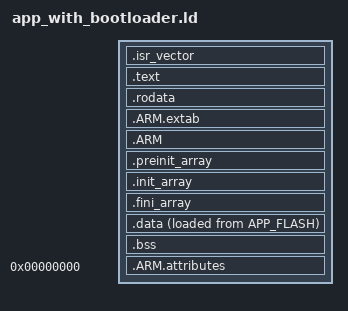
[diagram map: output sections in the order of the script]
/*
*****************************************************************************
**

**  File        : LinkerScript.ld
**
**  Abstract    : Linker script for STM32F4xx Device 
**
**                Set heap size, stack size and stack location according
**                to application requirements.
**
**                Set memory bank area and size if external memory is used.
**
**  Target      : STMicroelectronics STM32
**
**
**  Distribution: The file is distributed as is, without any warranty
**                of any kind.
**
**  (c)Copyright Ac6.
**  You may use this file as-is or modify it according to the needs of your
**  project. Distribution of this file (unmodified or modified) is not
**  permitted. Ac6 permit registered System Workbench for MCU users the
**  rights to distribute the assembled, compiled & linked contents of this
**  file as part of an application binary file, provided that it is built
**  using the System Workbench for MCU toolchain.
**
*****************************************************************************
*/

/* Entry Point */
ENTRY(Reset_Handler)

/* Include memory map */
INCLUDE memory.ld

_Min_Heap_Size = 0x7000;      /* required amount of heap  */
_Min_Stack_Size = 0x1000; /* required amount of stack */

/* Define output sections */
SECTIONS
{

  /* The startup code goes first into FLASH */
  .isr_vector :
  {
    . = ALIGN(8);
    KEEP(*(.isr_vector)) /* Startup code */
    . = ALIGN(8);
  } >APP_FLASH

  /* The program code and other data goes into FLASH */
  .text :
  {
    . = ALIGN(8);
    *(.text)           /* .text sections (code) */
    *(.text*)          /* .text* sections (code) */
    *(.glue_7)         /* glue arm to thumb code */
    *(.glue_7t)        /* glue thumb to arm code */
    *(.eh_frame)

    KEEP (*(.init))
    KEEP (*(.fini))

    . = ALIGN(8);
    _etext = .;        /* define a global symbols at end of code */
  } >APP_FLASH

  /* Constant data goes into FLASH */
  .rodata :
  {
    . = ALIGN(8);
    *(.rodata)         /* .rodata sections (constants, strings, etc.) */
    *(.rodata*)        /* .rodata* sections (constants, strings, etc.) */
    . = ALIGN(8);
  } >APP_FLASH

  .ARM.extab   : 
  { 
  . = ALIGN(8);
  *(.ARM.extab* .gnu.linkonce.armextab.*)
  . = ALIGN(8);
  } >APP_FLASH
  .ARM : {
	. = ALIGN(8);
    __exidx_start = .;
    *(.ARM.exidx*)
    __exidx_end = .;
	. = ALIGN(8);
  } >APP_FLASH

  .preinit_array     :
  {
	. = ALIGN(8);
    PROVIDE_HIDDEN (__preinit_array_start = .);
    KEEP (*(.preinit_array*))
    PROVIDE_HIDDEN (__preinit_array_end = .);
	. = ALIGN(8);
  } >APP_FLASH
  
  .init_array :
  {
	. = ALIGN(8);
    PROVIDE_HIDDEN (__init_array_start = .);
    KEEP (*(SORT(.init_array.*)))
    KEEP (*(.init_array*))
    PROVIDE_HIDDEN (__init_array_end = .);
	. = ALIGN(8);
  } >APP_FLASH
 
  .fini_array :
  {
	. = ALIGN(8);
    PROVIDE_HIDDEN (__fini_array_start = .);
    KEEP (*(SORT(.fini_array.*)))
    KEEP (*(.fini_array*))
    PROVIDE_HIDDEN (__fini_array_end = .);
	. = ALIGN(8);
  } >APP_FLASH
  

  /* used by the startup to initialize data */
  _sidata = LOADADDR(.data);

  /* Initialized data sections goes into RAM, load LMA copy after code */
  .data : 
  {
    . = ALIGN(8);
    _sdata = .;        /* create a global symbol at data start */
    *(.data)           /* .data sections */
    *(.data*)          /* .data* sections */

    . = ALIGN(8);
    _edata = .;        /* define a global symbol at data end */
  } >RAM AT> APP_FLASH

  
  /* Uninitialized data section */
  . = ALIGN(4);
  .bss :
  {
    /* This is used by the startup in order to initialize the .bss secion */
    _sbss = .;         /* define a global symbol at bss start */
    __bss_start__ = _sbss;
    *(.bss)
    *(.bss*)
    *(COMMON)

    . = ALIGN(4);
    _ebss = .;         /* define a global symbol at bss end */
    __bss_end__ = _ebss;
  } >RAM

  /* User_heap_stack section, used to check that there is enough RAM left */
    . = ALIGN(8);
    PROVIDE ( end = . );
    PROVIDE ( _end = . );
    PROVIDE (heap_start = . );
    PROVIDE( _estack = ALIGN( ORIGIN( RAM ) + LENGTH( RAM ) - 8, 8 ) );
	PROVIDE(_stack_unused      = _estack - _Min_Stack_Size);
    ASSERT ((_stack_unused > end), "Error: No room left for the stack")
	
    PROVIDE(heap_end      = _stack_unused);
    PROVIDE(heap_len      = heap_end -  heap_start);

    PROVIDE( heap2_start = ORIGIN( ERAM ));
    PROVIDE( heap2_len = LENGTH( ERAM ));
    .ARM.attributes 0 : { *(.ARM.attributes) }
}

 GROUP(
   libgcc.a
   libg.a
   libc.a
   libm.a
   libnosys.a
 )



